# YTM32B1ME1 register map
Vendor: YTMicro; File version: 1.0
CPU: CM33 r0p4, little endian, MPU, FPU, 2 interrupt priority bits
Registers are 32-bit, read-write, reset 0x0 unless marked. A register's access mark holds for its fields unless they carry their own. Offsets are from the block's base; [hi:lo] are bit positions; {n}, {i} and the like mark numbered series.

## EEPROM — Electrically Erasable Programmable Read-Only Memory
Base 0x4003C000; register names take the prefix EEPROM_
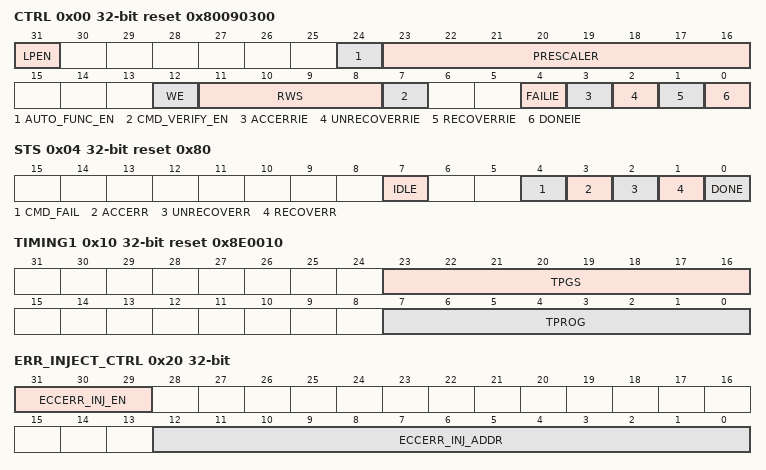
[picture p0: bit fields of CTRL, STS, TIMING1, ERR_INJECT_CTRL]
0x00 CTRL reset 0x80090300
  [31] LPEN — This LPEN bit determines whether the EEPROM array will enter low power mode when the MCU send a sleep request.
    0=EEPROM will keep active when the MCU send a sleep request; 1=EEPROM will enter low power mode when the MCU send a sleep request
  [24] AUTO_FUNC_EN — This AUTO_FUNC_EN bit determines whether enables automatic program function. ewline Once enable this bit, each data of AHB write transaction will be programmed to target address automatically.
    0=Disable the automatic program function; 1=Disable the automatic program function
  [23:16] PRESCALER — These PRESCALER bits are used for EEPROM operation time control. ewline Please use the following equation to calculate the PRESCALER value: ewline PRESCALER = APB clock frequency / 2 ewline Round up if not divisible. The unit of APB clock frequency is Mhz. ewline For example, if APB clock frequency is 40Mhz, PRESCALER value should be 20. ewline Please re-configure PRESCALER once the frequency is changed.
  [12] WE — This WE bit determines whether EEPROM is writable. Write access to EEPROM with WE is 0 will cause bus error.
    0=Disable EEPROM write; 1=Enable EEPROM write
  [11:8] RWS
  [7] CMD_VERIFY_EN — This CMD_VERIFY_EN bit determines whether to do verify read after erase or program operation during executing a command. ewline - After each program cycle, if CMD_VERIFY_EN=1, EEPROM should read the programmed address and compare the read data to program data, if not equal, set STATUS[CMD_CMD_FAIL] flag to 1. ewline - After each erase cycle, if CMD_VERIFY_EN=1, EEPROM should read the erased addresses and compare read data with FF, if read data are not all FF, set STATUS[CMD_CMD_FAIL] flag to 1.
    0=Disable verify read after erase or program cycle; 1=Enable verify read after erase or program cycle
  [4] FAILIE — This FAILIE bit determines whether the interrupt will be generated when STATUS[FAIL] flag is asserted.
    0=Don't generate interrupt when STATUS[FAIL] flag is asserted; 1=Generate interrupt when STATUS[FAIL] flag is asserted
  [3] ACCERRIE — This ACCERRIE bit determines whether the interrupt will be generated when STATUS[ACCERR] flag is asserted.
    0=Don't generate interrupt when STATUS[ACCERR] flag is asserted; 1=Generate interrupt when STATUS[ACCERR] flag is asserted
  [2] UNRECOVERRIE — This UNRECOVERRIE bit determines whether the interrupt will be generated when STATUS[UNRECOVERR] flag is asserted.
    0=Don't generate interrupt when STATUS[UNRECOVERR] flag is asserted; 1=Generate interrupt when STATUS[UNRECOVERR] flag is asserted
  [1] RECOVERRIE — This RECOVERRIE bit determines whether the interrupt will be generated when STATUS[RECOVERR] flag is asserted.
    0=Don't generate interrupt when STATUS[RECOVER] flag is asserted; 1=Generate interrupt when STATUS[RECOVERR] flag is asserted
  [0] DONEIE — This DONEIE bit determines whether the interrupt will be generated when DONE flag is asserted.
    0=Don't generate interrupt when STATUS[DONE] flag is asserted; 1=Generate interrupt when STATUS[DONE] flag is asserted
0x04 STS reset 0x80
  [7] IDLE ro — This IDLE bit indicates whether EEPROM is busy executing a command.
  [4] CMD_FAIL — This CMD_FAIL bit indicates whether the current command is failed. ewline Command failure includes below scenarios: ewline - Read check before a program cycle failed if data and ECC bits are not all FF. ewline - Verify check after a erase cycle failed if data and ECC bits are not cleared to all FF. ewline - Verify check after a program cycle failed if program data not equal to read data .
  [3] ACCERR — This ACCERR bit indicates whether an access error is detected. This flag is set after write EEPROM_CMD. When an access error occurred, the command is not launched. ewline Access error scenarios refer to \hyperref[flash-abnormal-operation]{EEPROM Abnormal Operation}.
    0=Access error is not detected; 1=Access error is detected
  [2] UNRECOVERR — This UNRECOVERR bit indicates whether more than 2-bit ECC error is detected during read EEPROM.
    0=No un-recovery ECC error is detected; 1=2-bit ECC error is detected
  [1] RECOVERR — This RECOVERR bit indicates whether there is a recovery ecc error is detected during EEPROM read.
    0=No recovery ECC error is detected; 1=1-bit ECC error is detected
  [0] DONE — This DONE bit indicates whether the current command is completed.
    0=Current command is in progress; 1=Current command is completed
0x08 CMD
  [7:0] CMD — These CMD bits determine which commands are available. Write valid command code to CMD to launch a command. Refer to table \hyperref[eeprom-commands]{EEPROM commands} for command code. ewline This register bit is reset by System Reset.
0x0C CMD_PROT
  [10:0] CMD_PROT — These CMD_PROT is used to disable commands. ewline Once bit CMD_PROTn is set HIGH, its corresponding command is disabled. Refer to \hyperref[eeprom-commands]{EEPROM commands} table for the map between commands and CMD_PROT bits ewline This register bit is reset by System Reset.
0x10 TIMING1 reset 0x8E0010
  [23:16] TPGS — These TPGS bits indicate the setup time of program. ewline The valid setup time of program is from 70us to 90us. The time unit of TPGS is 0.5us. So that the TPGS value range is 140 to 180. ewline For example, if TPGS value is 140, the EEPROM array program setup time is 140*0.5us=70us.
  [7:0] TPROG — These TPROG bits indicate the program pulse time. ewline The valid program pulse time is from 7us to 8.5us. The time unit of TPROG is 0.5us. So that the TPROG value range is 14 to 17. ewline For example, if TPROG value is 16, the EEPROM array program pulse time is 16*0.5us=8us.
0x14 TIMING2 reset 0xFA2
  [23:0] TERASE — These TERASE bits indicate the erase pulse times. ewline For Sector Erase, the valid erase pulse time is from 2ms to 3ms. ewline For Block Erase, the valid erase pulse time is from 30ms to 40ms. ewline The time unit of TERASE is 0.5us. For example, if TERASE value is 4000, the EEPROM array sector erase pulse time is 4000*0.5us=2ms.
0x20 ERR_INJECT_CTRL
  [31:29] ECCERR_INJ_EN — Set this ECCERR_INJ_EN bits while cause 1-bit/ 2-bit ECC error for any EEPROM reading.
    0=000b (Disable ECC error inject .); 1=001b (Inject 1-bit ECC error for target address.); 2=010b (Inject 2-bit ECC error for target address.); 5=101b (Inject 1-bit ECC error for any address.); 6=110b (Inject 2-bit ECC error for any address.)
  [12:0] ECCERR_INJ_ADDR — Please set target inject address of SOC main array before enable ecc error injection. ewline Once enable the ecc error injection, read target address of EEPROM will generate corresponding ecc error.
0x24 ADDR_PROT0 reset 0xFFFFFFFF
  [31:0] FLASH_ADDR_PROT — The address area of each EEPROM is divided into 32 regions. Each region is protected by one bit of ADDR_PROT. The address area of each region is 256B. ewline If any bit is set to 0, the corresponding region is under protection (read only). ewline During EEPROM initialization, ADDR_PROT registers load initial values from CUS_NVR of PEEPROM if the CUS_NVR has programmed with initial ADDR_PROT values with correct tag. ewline After initial done, software can write 0 to value 1 bit of ADDR_PROT, but can not write 1 to value 0 bit.
0x30 ECCERR_ADDR reset 0xFFFFFFFF
  [31:0] ERR_FLASH_ADDR ro — These bits records the first detected ECC error address. Followed ECC error addresses are not recorded. ewline When detecting an ECC error, hardware will set ECC error flag (RECOVERR or UNRECOVERR) and record information about error EEPROM address and error array. Read ECCERR_ADDR can get SOC accress of the recorded ECC error. ewline ECCERR_ADDR is cleared by writing 1 to the corresponding error flag. For example, if ECCERR_ADDR records UNRECOVERR address information, only write 1 to UNRECOVERR can clear ECCERR_ADDR, writing 1 to RECOVERR can not clear ECCERR_ADDR.
0x34 ECCERR_CNT
  [10:0] ECCERR_CNT ro — These ECCERR_CNT bits record 1-bit and 2-bit ECC errors.
0x200 CMD_UNLOCK
  [31:0] CMD_UNLOCK_KEY wo — Please write 0xfd9573f5 before launching a command
